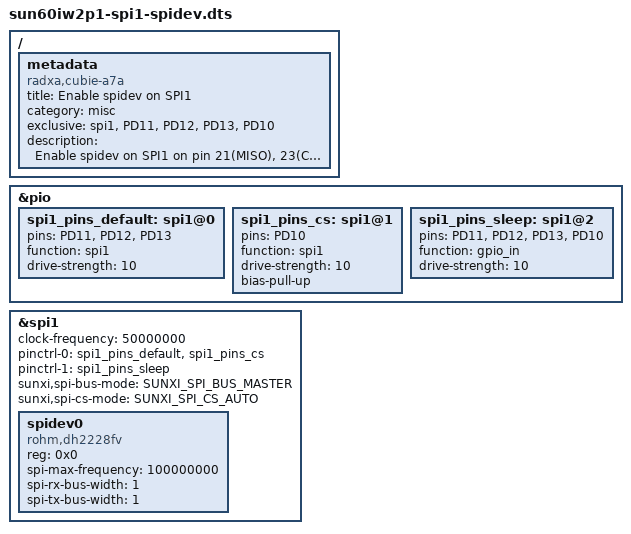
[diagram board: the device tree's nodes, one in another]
/dts-v1/;
/plugin/;
#include <dt-bindings/spi/sunxi-spi.h>

/{
	metadata {
		title = "Enable spidev on SPI1";
		compatible = "radxa,cubie-a7a", "radxa,cubie-a7z", "radxa,cubie-a7s";
		category = "misc";
		exclusive = "spi1", "PD11", "PD12", "PD13", "PD10";
		description = "Enable spidev on SPI1 on
pin 21(MISO), 23(CLK), 19(MOSI), 24(CS0)";
	};
};

&pio {
	spi1_pins_default: spi1@0 {
		pins = "PD11", "PD12", "PD13";
		function = "spi1";
		drive-strength = <10>;
	};

	spi1_pins_cs: spi1@1 {
		pins = "PD10";
		function = "spi1";
		drive-strength = <10>;
		bias-pull-up; /* cs, hold, wp should be pulled up */
	};

	spi1_pins_sleep: spi1@2 {
		pins = "PD11", "PD12", "PD13", "PD10";
		function = "gpio_in";
		drive-strength = <10>;
	};
};

&spi1 {
	clock-frequency = <50000000>;
	pinctrl-0 = <&spi1_pins_default &spi1_pins_cs>;
	pinctrl-1 = <&spi1_pins_sleep>;
	pinctrl-names = "default", "sleep";
	sunxi,spi-bus-mode = <SUNXI_SPI_BUS_MASTER>;
	sunxi,spi-cs-mode = <SUNXI_SPI_CS_AUTO>;
	status = "okay";

	spidev0 {
		compatible = "rohm,dh2228fv";
		reg = <0x0>;
		spi-max-frequency = <100000000>;
		spi-rx-bus-width = <1>;
		spi-tx-bus-width = <1>;
		status = "okay";	
	};
};
